# K32W041AM register map
Vendor: nxp.com; File version: 1.0
CPU: CM4 r0p1, little endian, MPU, no FPU, VTOR, 3 interrupt priority bits
Registers are 32-bit, read-write, reset 0x0 unless marked. A register's access mark holds for its fields unless they carry their own. Offsets are from the block's base; [hi:lo] are bit positions; {n}, {i} and the like mark numbered series.

## CTIMER0 — This is the description of component ct32b It is standard 32-bit Counter/Timer with APB bus interface. More details will follow.
Base 0x40021000
Same registers: CTIMER1 0x40022000
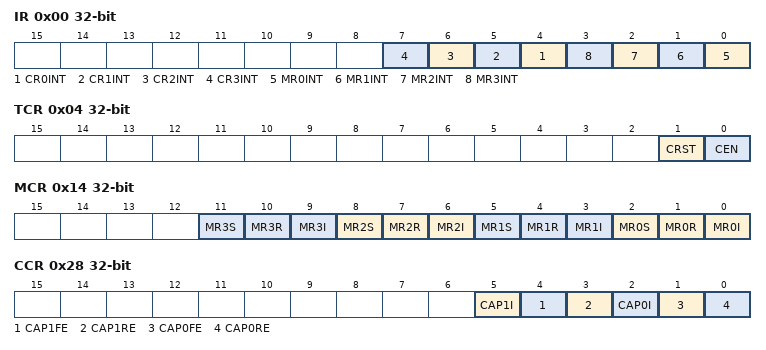
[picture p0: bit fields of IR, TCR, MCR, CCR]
0x00 IR — Interrupt Register. The IR can be written to clear interrupts. The IR can be read to identify which of eight possible interrupt sources are pending.
  [n+4] CR{n}INT (n=0..3) — Interrupt flag for capture channel {n} event.
  [n] MR{n}INT (n=0..3) — Interrupt flag for match channel {n}.
0x04 TCR — Timer Control Register. The TCR is used to control the Timer Counter functions. The Timer Counter can be disabled or reset through the TCR.
  [1] CRST — Counter reset. 0 Disabled. Do nothing. 1 Enabled. The Timer Counter and the Prescale Counter are synchronously reset on the next positive edge of the APB bus clock. The counters remain reset until TCR[1] is returned to zero.
  [0] CEN — Counter enable. 0 Disabled.The counters are disabled. 1 Enabled. The Timer Counter and Prescale Counter are enabled.
0x08 TC — Timer Counter. The 32 bit TC is incremented every PR+1 cycles of the APB bus clock. The TC is controlled through the TCR.
  [31:0] TCVAL — Timer counter value.
0x0C PR — Prescale Register. When the Prescale Counter (PC) is equal to this value, the next clock increments the TC and clears the PC.
  [31:0] PRVAL — Prescale counter value.
0x10 PC — Prescale Counter. The 32 bit PC is a counter which is incremented to the value stored in PR. When the value in PR is reached, the TC is incremented and the PC is cleared. The PC is observable and controllable through the bus interface.
  [31:0] PCVAL — Prescale counter value.
0x14 MCR — Match Control Register. The MCR is used to control if an interrupt is generated and if the TC is reset when a Match occurs.
  [3n+2] MR{n}S (n=0..3) — Stop on MR{n}: the TC and PC will be stopped and TCR[0] will be set to 0 if MR{n} matches the TC. 0 = disabled. 1 = enabled.
  [3n+1] MR{n}R (n=0..3) — Reset on MR{n}: the TC will be reset if MR{n} matches it. 0 = disabled. 1 = enabled.
  [3n] MR{n}I (n=0..3) — Interrupt on MR{n}: an interrupt is generated when MR{n} matches the value in the TC. 0 = disabled. 1 = enabled.
{0x18+4i} MR[{i}] (i=0..3) — Match Register . MR can be enabled through the MCR to reset the TC, stop both the TC and PC, and/or generate an interrupt every time MR matches the TC.
  [31:0] MATCH — Timer counter match value.
0x28 CCR — Capture Control Register. The CCR controls which edges of the capture inputs are used to load the Capture Registers and whether or not an interrupt is generated when a capture takes place.
  [5] CAP1I — Generate interrupt on channel 1 capture event: a CR1 load generates an interrupt.
  [4] CAP1FE — Falling edge of capture channel 1: a sequence of 1 then 0 causes CR1 to be loaded with the contents of TC. 0 = disabled. 1 = enabled.
  [3] CAP1RE — Rising edge of capture channel 1: a sequence of 0 then 1 causes CR1 to be loaded with the contents of TC. 0 = disabled. 1 = enabled.
  [2] CAP0I — Generate interrupt on channel 0 capture event: a CR0 load generates an interrupt.
  [1] CAP0FE — Falling edge of capture channel 0: a sequence of 1 then 0 causes CR0 to be loaded with the contents of TC. 0 = disabled. 1 = enabled.
  [0] CAP0RE — Rising edge of capture channel 0: a sequence of 0 then 1 causes CR0 to be loaded with the contents of TC. 0 = disabled. 1 = enabled.
{0x2C+4i} CR[{i}] (i=0..1) ro — Capture Register . CR is loaded with the value of TC when there is an event on the CAPn.0 input.
  [31:0] CAP — Timer counter capture value.
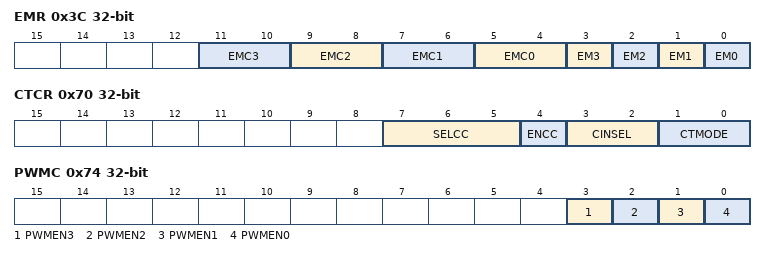
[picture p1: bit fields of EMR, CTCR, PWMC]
0x3C EMR — External Match Register. The EMR controls the match function and the external match pins.
  [2n+5:2n+4] EMC{n} (n=0..3) — External Match Control {n}. Determines the functionality of External Match {n}. 0x0 Do Nothing. 0x1 Clear. Clear the corresponding External Match bit/output to 0 (MAT{n} pin is LOW if pinned out). 0x2 Set. Set the corresponding External Match bit/output to 1 (MAT{n} pin is HIGH if pinned out). 0x3 Toggle. Toggle the corresponding External Match bit/output.
  [3] EM3 — External Match 3. This bit reflects the state of output MAT3, whether or not this output is connected to a pin. When a match occurs between the TC and MR3, this bit can either toggle, go LOW, go HIGH, or do nothing, as selected by MR[11:10]. This bit is driven to the MAT pins if the match function is selected via IOCON. 0 = LOW. 1 = HIGH.
  [2] EM2 — External Match 2. This bit reflects the state of output MAT2, whether or not this output is connected to a pin. When a match occurs between the TC and MR2, this bit can either toggle, go LOW, go HIGH, or do nothing, as selected by EMR[9:8]. This bit is driven to the MAT pins if the match function is selected via IOCON. 0 = LOW. 1 = HIGH
  [1] EM1 — External Match 1. This bit reflects the state of output MAT1, whether or not this output is connected to a pin. When a match occurs between the TC and MR1, this bit can either toggle, go LOW, go HIGH, or do nothing, as selected by EMR[7:6]. This bit is driven to the MAT pins if the match function is selected via IOCON. 0 = LOW. 1 = HIGH.
  [0] EM0 — External Match 0. This bit reflects the state of output MAT0, whether or not this output is connected to a pin. When a match occurs between the TC and MR0, this bit can either toggle, go LOW, go HIGH, or do nothing, as selected by EMR[5:4]. This bit is driven to the MAT pins if the match function is selected via IOCON. 0 = LOW. 1 = HIGH.
0x70 CTCR — Count Control Register. The CTCR selects between Timer and Counter mode, and in Counter mode selects the signal and edge(s) for counting.
  [7:5] SELCC — Edge select. When bit 4 is 1, these bits select which capture input edge will cause the timer and prescaler to be cleared. These bits have no effect when bit 4 is low. Values 0x2 to 0x3 and 0x6 to 0x7 are reserved. 0 0x0 Channel 0 Rising Edge. Rising edge of the signal on capture channel 0 clears the timer (if bit 4 is set). 0x1 Channel 0 Falling Edge. Falling edge of the signal on capture channel 0 clears the timer (if bit 4 is set). 0x2 Channel 1 Rising Edge. Rising edge of the signal on capture channel 1 clears the timer (if bit 4 is set). 0x3 Channel 1 Falling Edge. Falling edge of the signal on capture channel 1 clears the timer (if bit 4 is set). 0x4 Channel 2 Rising Edge. Rising edge of the signal on capture channel 2 clears the timer (if bit 4 is set). 0x5 Channel 2 Falling Edge. Falling edge of the signal on capture channel 2 clears the timer (if bit 4 is set).
  [4] ENCC — Setting this bit to 1 enables clearing of the timer and the prescaler when the capture-edge event specified in bits 7:5 occurs.
  [3:2] CINSEL — Count Input Select When bits 1:0 in this register are not 00, these bits select which CAP pin is sampled for clocking. Note: If Counter mode is selected for a particular CAPn input in the CTCR, the 3 bits for that input in the Capture Control Register (CCR) must be programmed as 000. However, capture and/or interrupt can be selected for the other 3 CAPn inputs in the same timer. 0x0 Channel 0. CAPn.0 for CT32Bn 0x1 Channel 1. CAPn.1 for CT32Bn 0x2 Channel 2. CAPn.2 for CT32Bn 0x3 Channel 3. CAPn.3 for CT32Bn
  [1:0] CTMODE — Counter/Timer Mode This field selects which rising APB bus clock edges can increment Timer s Prescale Counter (PC), or clear PC and increment Timer Counter (TC). Timer Mode: the TC is incremented when the Prescale Counter matches the Prescale Register. 0x0 Timer Mode. Incremented every rising APB bus clock edge. 0x1 Counter Mode rising edge. TC is incremented on rising edges on the CAP input selected by bits 3:2. 0x2 Counter Mode falling edge. TC is incremented on falling edges on the CAP input selected by bits 3:2. 0x3 Counter Mode dual edge. TC is incremented on both edges on the CAP input selected by bits 3:2.
0x74 PWMC — PWM Control Register. The PWMCON enables PWM mode for the external match pins.
  [3] PWMEN3 — PWM mode enable for channel3. Note: It is recommended to use match channel 3 to set the PWM cycle. 0 Match. CT32Bn_MAT3 is controlled by EM3. 1 PWM. PWM mode is enabled for CT132Bn_MAT3
  [2] PWMEN2 — PWM mode enable for channel2. 0 Match. CT32Bn_MAT2 is controlled by EM2. 1 PWM. PWM mode is enabled for CT32Bn_MAT2.
  [1] PWMEN1 — PWM mode enable for channel1. 0 Match. CT32Bn_MAT01 is controlled by EM1. 1 PWM. PWM mode is enabled for CT32Bn_MAT1.
  [0] PWMEN0 — PWM mode enable for channel0. 0 Match. CT32Bn_MAT0 is controlled by EM0. 1 PWM. PWM mode is enabled for CT32Bn_MAT0.
